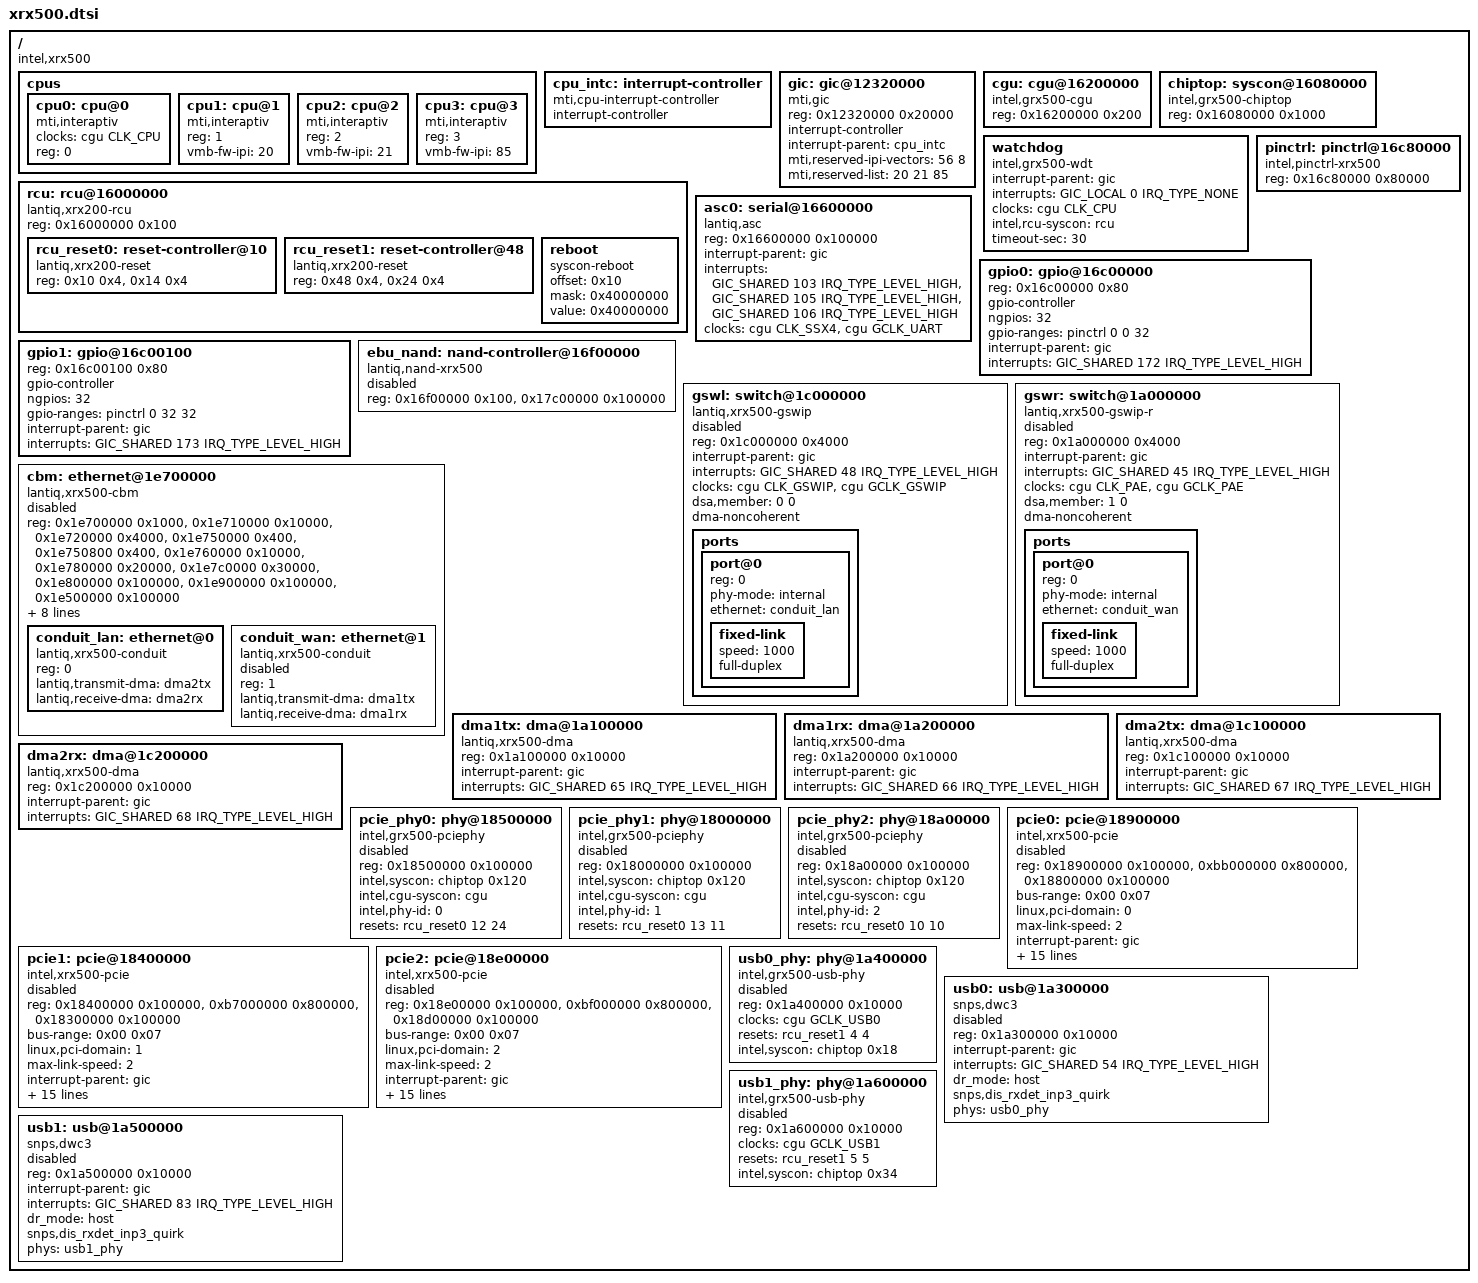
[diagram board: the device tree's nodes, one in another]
// SPDX-License-Identifier: GPL-2.0-only
// Copyright (C) 2026 Grische <github@grische.xyz>

#include <dt-bindings/interrupt-controller/mips-gic.h>
#include <dt-bindings/clock/intel,grx500-clk.h>

/ {
	#address-cells = <1>;
	#size-cells = <1>;
	compatible = "intel,xrx500";

	/*
	 * Two interAptiv cores, two VPEs each. Only cpu0 carries clocks:
	 * time.c reads the rate from node 0. The vmb-fw-ipi numbers are
	 * firmware-owned — the same three values appear in the vendor device
	 * tree — and are repeated in mti,reserved-list so nothing else claims
	 * them.
	 */
	cpus {
		#address-cells = <1>;
		#size-cells = <0>;

		cpu0: cpu@0 {
			device_type = "cpu";
			compatible = "mti,interaptiv";
			clocks = <&cgu CLK_CPU>;
			reg = <0>;
		};

		cpu1: cpu@1 {
			device_type = "cpu";
			compatible = "mti,interaptiv";
			reg = <1>;
			vmb-fw-ipi = <20>;
		};

		cpu2: cpu@2 {
			device_type = "cpu";
			compatible = "mti,interaptiv";
			reg = <2>;
			vmb-fw-ipi = <21>;
		};

		cpu3: cpu@3 {
			device_type = "cpu";
			compatible = "mti,interaptiv";
			reg = <3>;
			vmb-fw-ipi = <85>;
		};
	};

	cpu_intc: interrupt-controller {
		compatible = "mti,cpu-interrupt-controller";

		interrupt-controller;
		#address-cells = <0>;
		#interrupt-cells = <1>;
	};

	gic: gic@12320000 {
		compatible = "mti,gic";
		reg = <0x12320000 0x20000>;

		interrupt-controller;
		#interrupt-cells = <3>;
		/*
		 * Declare the interrupt-parent even though the mti,gic
		 * binding doesn't require it, such that the kernel can
		 * figure out that cpu_intc is the root interrupt
		 * controller & should be probed first.
		 */
		interrupt-parent = <&cpu_intc>;
		mti,reserved-ipi-vectors = <56 8>;

		/*
		 * The doorbells the CPU-launch firmware owns. They are shared
		 * GIC interrupts and must stay out of the kernel's IPI pool.
		 */
		mti,reserved-list = <20 21 85>;
	};

	cgu: cgu@16200000 {
		compatible = "intel,grx500-cgu", "syscon";
		reg = <0x16200000 0x200>;
		#clock-cells = <1>;
	};

	/*
	 * Chip-top configuration block: a pure syscon. Consumers reach single
	 * fields through a phandle plus an offset.
	 */
	chiptop: syscon@16080000 {
		compatible = "intel,grx500-chiptop", "syscon";
		reg = <0x16080000 0x1000>;
	};

	/*
	 * Reset Control Unit. The mainline lantiq,xrx200-reset driver must be
	 * a syscon child: its reg is a byte offset into the parent regmap,
	 * not an absolute address.
	 *
	 * #reset-cells = <2> is [set_bit, status_bit]: the driver sets the
	 * request bit in the first register and then polls the status bit in
	 * the second one. On this SoC those are usually *different* numbers.
	 * RCU_RST_STAT is a remap of RCU_RST_REQ, not a mirror of it, so a
	 * second cell that repeats the first is a bug and not a convention --
	 * the poll then watches an unrelated bit and can only end in a
	 * timeout. The per-domain map for the lines this device tree drives,
	 * in the first bank:
	 *
	 *	line				REQ	STAT
	 *	pcie_phy0			12	24
	 *	pcie_phy1			13	11
	 *	pcie_phy2			10	10
	 *	gphy@f8a			29	28
	 *	gphy@f8e			28	23
	 *	gphy@f92			26	22
	 *	gphy@f96			25	25
	 *	gphy@f9a (GRX550 only)		31	30
	 *
	 * Two positions in RCU_RST_STAT are reset *causes* rather than line
	 * statuses, and neither is the status of the line whose request bit
	 * sits at the same index: bit 31 is the watchdog, which the watchdog
	 * node below reads through this same syscon, and bit 29 is the global
	 * software reset that the reboot node requests with RCU_RST_REQ bit
	 * 30. Bit 31 therefore means one thing in the request register -- the
	 * fifth GPHY's line -- and something else entirely in the status
	 * register.
	 */
	rcu: rcu@16000000 {
		compatible = "lantiq,xrx200-rcu", "simple-mfd", "syscon";
		reg = <0x16000000 0x100>;
		ranges = <0x0 0x16000000 0x100>;
		#address-cells = <1>;
		#size-cells = <1>;

		rcu_reset0: reset-controller@10 {
			compatible = "lantiq,xrx200-reset";
			reg = <0x10 0x4>, <0x14 0x4>;
			#reset-cells = <2>;
		};

		/*
		 * Second reset bank. RCU_RST_REQ2 is at 0x48 and
		 * RCU_RST_STAT2 at 0x24. Both lines this device tree takes
		 * from it, the two USB PHYs, are among the domains whose
		 * status bit does repeat the request bit, so a vendor reset id
		 * of 5 translates to <&rcu_reset1 5 5>.
		 */
		rcu_reset1: reset-controller@48 {
			compatible = "lantiq,xrx200-reset";
			reg = <0x48 0x4>,	/* RCU_RST_REQ2 */
			      <0x24 0x4>;	/* RCU_RST_STAT2 */
			#reset-cells = <2>;
		};

		/*
		 * Restart handler. Bit 30 of RCU_RST_REQ triggers the SoC
		 * reset, and the write must be a read-modify-write under the
		 * mask: a legacy full-word write clears reset lines that are
		 * latched elsewhere in the same register.
		 */
		reboot {
			compatible = "syscon-reboot";
			offset = <0x10>;	/* RCU_RST_REQ */
			mask = <0x40000000>;	/* RCU_RD_SRST */
			value = <0x40000000>;
		};
	};

	/*
	 * There is no watchdog block on this SoC — the timer is the GIC's
	 * per-VP watchdog — so this node carries no reg and no unit address.
	 * The RCU phandle supplies the reset-enable bit and the reset-cause
	 * word. The interrupt is per-VP and optional.
	 */
	watchdog {
		compatible = "intel,grx500-wdt";

		interrupt-parent = <&gic>;
		interrupts = <GIC_LOCAL 0 IRQ_TYPE_NONE>;
		clocks = <&cgu CLK_CPU>;
		intel,rcu-syscon = <&rcu>;
		timeout-sec = <30>;
	};

	asc0: serial@16600000 {
		compatible = "lantiq,asc";
		reg = <0x16600000 0x100000>;

		interrupt-parent = <&gic>;
		interrupts = <GIC_SHARED 103 IRQ_TYPE_LEVEL_HIGH>,
			<GIC_SHARED 105 IRQ_TYPE_LEVEL_HIGH>,
			<GIC_SHARED 106 IRQ_TYPE_LEVEL_HIGH>;
		clocks = <&cgu CLK_SSX4>, <&cgu GCLK_UART>;
		clock-names = "freq", "asc";
	};

	/*
	 * Equilibrium pinmux / pad controller. eqbr_build_groups() walks
	 * every child, enabled or not, and returns -EINVAL for the first one
	 * that has "groups" but neither "pins" nor "pinmux" — which fails the
	 * whole pinctrl probe, not just that group. Pin groups therefore live
	 * in the narrowest file that needs them.
	 */
	pinctrl: pinctrl@16c80000 {
		compatible = "intel,pinctrl-xrx500";
		reg = <0x16c80000 0x80000>;
	};

	/*
	 * GPIO banks. Three constraints that are invisible in the code:
	 *
	 * - The node order matters: the driver walks them with a global
	 * for_each_node_by_name().
	 * - gpio-ranges spans 32 pins, not the 30 that are wired:
	 *   bgpio_init() needs
	 * a power-of-two register width.
	 * - interrupts is mandatory even where nothing uses it, because
	 *   gpiolib_reg()
	 * always parses it.
	 */
	gpio0: gpio@16c00000 {
		reg = <0x16c00000 0x80>;

		gpio-controller;
		#gpio-cells = <2>;
		ngpios = <32>;
		gpio-ranges = <&pinctrl 0 0 32>;

		interrupt-parent = <&gic>;
		interrupts = <GIC_SHARED 172 IRQ_TYPE_LEVEL_HIGH>;
	};

	gpio1: gpio@16c00100 {
		reg = <0x16c00100 0x80>;

		gpio-controller;
		#gpio-cells = <2>;
		ngpios = <32>;
		gpio-ranges = <&pinctrl 0 32 32>;

		interrupt-parent = <&gic>;
		interrupts = <GIC_SHARED 173 IRQ_TYPE_LEVEL_HIGH>;
	};

	ebu_nand: nand-controller@16f00000 {
		compatible = "lantiq,nand-xrx500";
		/*
		 * Two reg blocks: the EBU register window (256 bytes at
		 * 0x16f00000) and the chip-select-1 NAND data window
		 * (1 MiB at 0x17c00000). The CS1 window is fixed by the
		 * EBU's ADDR_SEL1 region map (ADDR_MASK(5) on xRX500
		 * selects a 1 MiB aperture starting at 0x17c00000).
		 */
		reg = <0x16f00000 0x100>,
		      <0x17c00000 0x100000>;
		reg-names = "ebunand", "nand_cs1";
		#address-cells = <1>;
		#size-cells = <0>;
		status = "disabled";
	};

	/*
	 * The two GSWIP-3.0 switch macros. One window each covers the switch
	 * core, the macro's top block and the packet MAC, so the MDIO bus and
	 * the loader for the integrated PHYs are children with no window of
	 * their own.
	 *
	 * Two trees rather than two switches in one tree: a conduit carries
	 * exactly one CPU port, and nothing forwards between the macros in
	 * hardware, so a bridge spanning both would blackhole.
	 *
	 * dma-noncoherent is not decoration. The PHY cores fetch their
	 * firmware without taking part in the platform's cache coherence, so
	 * the staged image has to be written back before they are released.
	 *
	 * Each macro is fed by a divider off the second PLL and a gate of its
	 * own, and neither is shared with anything else on the die. The two
	 * macros sit on different branches of that PLL, which is why the pair
	 * differs between them.
	 *
	 * One line each aggregates everything the macro can report: the buffer
	 * manager, the parser and classification engine, the MAC block and the
	 * store and fetch DMA blocks. Nothing takes it yet; the driver reaches
	 * the same state by polling.
	 */
	gswl: switch@1c000000 {
		compatible = "lantiq,xrx500-gswip";
		reg = <0x1c000000 0x4000>;
		interrupt-parent = <&gic>;
		interrupts = <GIC_SHARED 48 IRQ_TYPE_LEVEL_HIGH>;
		clocks = <&cgu CLK_GSWIP>, <&cgu GCLK_GSWIP>;
		clock-names = "freq", "gate";
		dsa,member = <0 0>;
		dma-noncoherent;
		status = "disabled";

		ports {
			#address-cells = <1>;
			#size-cells = <0>;

			/*
			 * The CPU port. Which conduit it reaches is on the die
			 * and not on the board: this macro's frames leave over
			 * the second pair of DMA controllers and no other.
			 */
			port@0 {
				reg = <0>;
				phy-mode = "internal";
				ethernet = <&conduit_lan>;

				fixed-link {
					speed = <1000>;
					full-duplex;
				};
			};
		};
	};

	gswr: switch@1a000000 {
		compatible = "lantiq,xrx500-gswip-r";
		reg = <0x1a000000 0x4000>;
		interrupt-parent = <&gic>;
		interrupts = <GIC_SHARED 45 IRQ_TYPE_LEVEL_HIGH>;
		clocks = <&cgu CLK_PAE>, <&cgu GCLK_PAE>;
		clock-names = "freq", "gate";
		dsa,member = <1 0>;
		dma-noncoherent;
		status = "disabled";

		ports {
			#address-cells = <1>;
			#size-cells = <0>;

			port@0 {
				reg = <0>;
				phy-mode = "internal";
				ethernet = <&conduit_wan>;

				fixed-link {
					speed = <1000>;
					full-duplex;
				};
			};
		};
	};

	/*
	 * Packet buffer manager. It owns the segment pools every packet on the
	 * datapath is held in, the enqueue and dequeue managers, the traffic
	 * manager between them, and the table binding an endpoint to a queue.
	 * Both switch macros and all four DMA controllers draw from it.
	 *
	 * A conduit is a processor's end of one macro's datapath and owns no
	 * window of its own, so it is a child of this node. There are two of
	 * them because a conduit carries exactly one CPU port.
	 */
	cbm: ethernet@1e700000 {
		compatible = "lantiq,xrx500-cbm";
		reg = <0x1e700000 0x1000>,    /* tmu      */
		      <0x1e710000 0x10000>,   /* cbm      */
		      <0x1e720000 0x4000>,    /* qidt     */
		      <0x1e750000 0x400>,     /* qeqcnt   */
		      <0x1e750800 0x400>,     /* qdqcnt   */
		      <0x1e760000 0x10000>,   /* ls       */
		      <0x1e780000 0x20000>,   /* eqm      */
		      <0x1e7c0000 0x30000>,   /* dqm      */
		      <0x1e800000 0x100000>,  /* fsqm0    */
		      <0x1e900000 0x100000>,  /* fsqm1    */
		      <0x1e500000 0x100000>;  /* dma-desc */
		reg-names = "tmu", "cbm", "qidt", "qeqcnt", "qdqcnt", "ls",
			    "eqm", "dqm", "fsqm0", "fsqm1", "dma-desc";
		interrupt-parent = <&gic>;
		interrupts = <GIC_SHARED 174 IRQ_TYPE_LEVEL_HIGH>,
			     <GIC_SHARED 178 IRQ_TYPE_LEVEL_HIGH>,
			     <GIC_SHARED 179 IRQ_TYPE_LEVEL_HIGH>,
			     <GIC_SHARED 180 IRQ_TYPE_LEVEL_HIGH>,
			     <GIC_SHARED 181 IRQ_TYPE_LEVEL_HIGH>;
		interrupt-names = "cbm", "ls0", "ls1", "ls2", "ls3";
		clocks = <&cgu CLK_CBM>, <&cgu GCLK_CBM>;
		clock-names = "freq", "cbm";
		#address-cells = <1>;
		#size-cells = <0>;
		status = "disabled";

		conduit_lan: ethernet@0 {
			compatible = "lantiq,xrx500-conduit";
			reg = <0>;
			lantiq,transmit-dma = <&dma2tx>;
			lantiq,receive-dma = <&dma2rx>;
		};

		/*
		 * The second macro carries a front-panel socket only on the
		 * die variant that wires one, so its conduit is left to the
		 * board files to enable.
		 */
		conduit_wan: ethernet@1 {
			compatible = "lantiq,xrx500-conduit";
			reg = <1>;
			lantiq,transmit-dma = <&dma1tx>;
			lantiq,receive-dma = <&dma1rx>;
			status = "disabled";
		};
	};

	/*
	 * The four packet DMA controllers, a transmit and a receive one for
	 * each switch macro. Their channels are hard-bound to a macro and to a
	 * port of the buffer manager, so they offer nothing to an arbitrary
	 * consumer and are reached through the phandle of the endpoint that
	 * uses them. How each instance arbitrates, bursts, polls and places
	 * its descriptors is fixed by the die and belongs to the driver.
	 */
	dma1tx: dma@1a100000 {
		compatible = "lantiq,xrx500-dma";
		reg = <0x1a100000 0x10000>;
		interrupt-parent = <&gic>;
		interrupts = <GIC_SHARED 65 IRQ_TYPE_LEVEL_HIGH>;
	};

	dma1rx: dma@1a200000 {
		compatible = "lantiq,xrx500-dma";
		reg = <0x1a200000 0x10000>;
		interrupt-parent = <&gic>;
		interrupts = <GIC_SHARED 66 IRQ_TYPE_LEVEL_HIGH>;
	};

	dma2tx: dma@1c100000 {
		compatible = "lantiq,xrx500-dma";
		reg = <0x1c100000 0x10000>;
		interrupt-parent = <&gic>;
		interrupts = <GIC_SHARED 67 IRQ_TYPE_LEVEL_HIGH>;
	};

	dma2rx: dma@1c200000 {
		compatible = "lantiq,xrx500-dma";
		reg = <0x1c200000 0x10000>;
		interrupt-parent = <&gic>;
		interrupts = <GIC_SHARED 68 IRQ_TYPE_LEVEL_HIGH>;
	};

	/*
	 * Three independent Synopsys DesignWare root complexes, each with its
	 * own serdes PHY and its own chip-top byte-swap configuration.
	 */

	/*
	 * Serdes PHYs. Both syscon phandles are mandatory: one carries the
	 * PHY configuration word and the other the reset. intel,phy-id has no
	 * fallback — the driver cannot derive it — and the second reset
	 * cell is the status bit the line reports through, which is a
	 * different number from the request bit on two of the three: see the
	 * map on the reset controller above.
	 */
	pcie_phy0: phy@18500000 {
		compatible = "intel,grx500-pciephy";
		reg = <0x18500000 0x100000>;
		reg-names = "phy";
		#phy-cells = <0>;
		intel,syscon = <&chiptop 0x120>;
		intel,cgu-syscon = <&cgu>;
		intel,phy-id = <0>;
		resets = <&rcu_reset0 12 24>;
		reset-names = "phy";
		status = "disabled";
	};

	pcie_phy1: phy@18000000 {
		compatible = "intel,grx500-pciephy";
		reg = <0x18000000 0x100000>;
		reg-names = "phy";
		#phy-cells = <0>;
		intel,syscon = <&chiptop 0x120>;
		intel,cgu-syscon = <&cgu>;
		intel,phy-id = <1>;
		resets = <&rcu_reset0 13 11>;
		reset-names = "phy";
		status = "disabled";
	};

	pcie_phy2: phy@18a00000 {
		compatible = "intel,grx500-pciephy";
		reg = <0x18a00000 0x100000>;
		reg-names = "phy";
		#phy-cells = <0>;
		intel,syscon = <&chiptop 0x120>;
		intel,cgu-syscon = <&cgu>;
		intel,phy-id = <2>;
		resets = <&rcu_reset0 10 10>;
		reset-names = "phy";
		status = "disabled";
	};

	/*
	 * Root complexes. Three requirements the code cannot show:
	 *
	 * - The window must be named "config": pcie-designware-host.c looks
	 *   it up by name.
	 * - bus-range stops at 7 because the config accessor masks the bus
	 *   number to three bits.
	 * - device_type = "pci" is required for the OF PCI bus parser to
	 *   accept the node.
	 */
	pcie0: pcie@18900000 {
		compatible = "intel,xrx500-pcie";
		device_type = "pci";
		reg = <0x18900000 0x100000>,	/* DWC core registers (DBI) */
		      <0xbb000000 0x800000>,	/* configuration space */
		      <0x18800000 0x100000>;	/* application logic */
		reg-names = "dbi", "config", "app";
		#address-cells = <3>;
		#size-cells = <2>;
		bus-range = <0x00 0x07>;
		ranges = <0x02000000 0 0xb8000000 0xb8000000 0 0x03000000>;
		linux,pci-domain = <0>;
		max-link-speed = <2>;

		interrupt-parent = <&gic>;
		interrupts = <GIC_SHARED 152 IRQ_TYPE_LEVEL_HIGH>;
		interrupt-names = "ir";
		#interrupt-cells = <1>;
		interrupt-map-mask = <0 0 0 0x7>;
		interrupt-map = <0 0 0 1 &gic GIC_SHARED 136 IRQ_TYPE_LEVEL_HIGH>,
				<0 0 0 2 &gic GIC_SHARED 137 IRQ_TYPE_LEVEL_HIGH>,
				<0 0 0 3 &gic GIC_SHARED 138 IRQ_TYPE_LEVEL_HIGH>,
				<0 0 0 4 &gic GIC_SHARED 139 IRQ_TYPE_LEVEL_HIGH>;

		clocks = <&cgu GCLK_PCIE0>;
		phys = <&pcie_phy0>;
		phy-names = "pcie";

		intel,syscon = <&chiptop 0x4c>;
		intel,inbound-shift = <5>;
		intel,outbound-shift = <4>;
		status = "disabled";
	};

	pcie1: pcie@18400000 {
		compatible = "intel,xrx500-pcie";
		device_type = "pci";
		reg = <0x18400000 0x100000>,	/* DWC core registers (DBI) */
		      <0xb7000000 0x800000>,	/* configuration space */
		      <0x18300000 0x100000>;	/* application logic */
		reg-names = "dbi", "config", "app";
		#address-cells = <3>;
		#size-cells = <2>;
		bus-range = <0x00 0x07>;
		ranges = <0x02000000 0 0xb4000000 0xb4000000 0 0x03000000>;
		linux,pci-domain = <1>;
		max-link-speed = <2>;

		interrupt-parent = <&gic>;
		interrupts = <GIC_SHARED 49 IRQ_TYPE_LEVEL_HIGH>;
		interrupt-names = "ir";
		#interrupt-cells = <1>;
		interrupt-map-mask = <0 0 0 0x7>;
		interrupt-map = <0 0 0 1 &gic GIC_SHARED 9 IRQ_TYPE_LEVEL_HIGH>,
				<0 0 0 2 &gic GIC_SHARED 10 IRQ_TYPE_LEVEL_HIGH>,
				<0 0 0 3 &gic GIC_SHARED 11 IRQ_TYPE_LEVEL_HIGH>,
				<0 0 0 4 &gic GIC_SHARED 12 IRQ_TYPE_LEVEL_HIGH>;

		clocks = <&cgu GCLK_PCIE1>;
		phys = <&pcie_phy1>;
		phy-names = "pcie";

		intel,syscon = <&chiptop 0x4c>;
		intel,inbound-shift = <9>;
		intel,outbound-shift = <8>;
		status = "disabled";
	};

	pcie2: pcie@18e00000 {
		compatible = "intel,xrx500-pcie";
		device_type = "pci";
		reg = <0x18e00000 0x100000>,	/* DWC core registers (DBI) */
		      <0xbf000000 0x800000>,	/* configuration space */
		      <0x18d00000 0x100000>;	/* application logic */
		reg-names = "dbi", "config", "app";
		#address-cells = <3>;
		#size-cells = <2>;
		bus-range = <0x00 0x07>;
		ranges = <0x02000000 0 0xbc000000 0xbc000000 0 0x03000000>;
		linux,pci-domain = <2>;
		max-link-speed = <2>;

		interrupt-parent = <&gic>;
		interrupts = <GIC_SHARED 55 IRQ_TYPE_LEVEL_HIGH>;
		interrupt-names = "ir";
		#interrupt-cells = <1>;
		interrupt-map-mask = <0 0 0 0x7>;
		interrupt-map = <0 0 0 1 &gic GIC_SHARED 155 IRQ_TYPE_LEVEL_HIGH>,
				<0 0 0 2 &gic GIC_SHARED 156 IRQ_TYPE_LEVEL_HIGH>,
				<0 0 0 3 &gic GIC_SHARED 157 IRQ_TYPE_LEVEL_HIGH>,
				<0 0 0 4 &gic GIC_SHARED 158 IRQ_TYPE_LEVEL_HIGH>;

		clocks = <&cgu GCLK_PCIE2>;
		phys = <&pcie_phy2>;
		phy-names = "pcie";

		intel,syscon = <&chiptop 0x4c>;
		intel,inbound-shift = <13>;
		intel,outbound-shift = <12>;
		status = "disabled";
	};

	/*
	 * Two Synopsys DesignWare USB3 DRD controllers, described as plain
	 * snps,dwc3 nodes. The PHY driver owns the chip-top AXI endianness
	 * word; intel,syscon's argument is that controller's AXI
	 * configuration offset.
	 */
	usb0_phy: phy@1a400000 {
		compatible = "intel,grx500-usb-phy";
		reg = <0x1a400000 0x10000>;
		#phy-cells = <0>;
		clocks = <&cgu GCLK_USB0>;
		resets = <&rcu_reset1 4 4>;
		reset-names = "phy";
		intel,syscon = <&chiptop 0x18>;
		status = "disabled";
	};

	usb0: usb@1a300000 {
		compatible = "snps,dwc3";
		reg = <0x1a300000 0x10000>;

		interrupt-parent = <&gic>;
		interrupts = <GIC_SHARED 54 IRQ_TYPE_LEVEL_HIGH>;

		dr_mode = "host";
		snps,dis_rxdet_inp3_quirk;
		phys = <&usb0_phy>;
		phy-names = "usb3-phy";
		status = "disabled";
	};

	usb1_phy: phy@1a600000 {
		compatible = "intel,grx500-usb-phy";
		reg = <0x1a600000 0x10000>;
		#phy-cells = <0>;
		clocks = <&cgu GCLK_USB1>;
		resets = <&rcu_reset1 5 5>;
		reset-names = "phy";
		intel,syscon = <&chiptop 0x34>;
		status = "disabled";
	};

	usb1: usb@1a500000 {
		compatible = "snps,dwc3";
		reg = <0x1a500000 0x10000>;

		interrupt-parent = <&gic>;
		interrupts = <GIC_SHARED 83 IRQ_TYPE_LEVEL_HIGH>;

		dr_mode = "host";
		snps,dis_rxdet_inp3_quirk;
		phys = <&usb1_phy>;
		phy-names = "usb3-phy";
		status = "disabled";
	};
};
